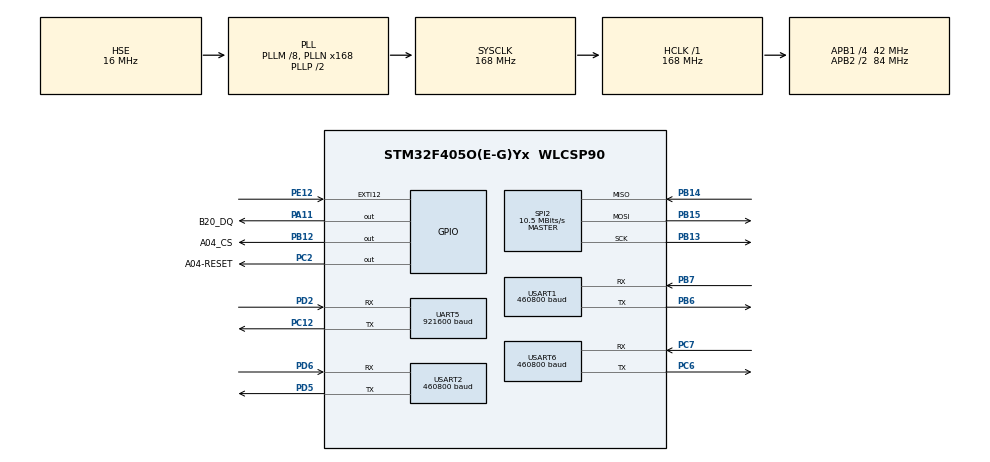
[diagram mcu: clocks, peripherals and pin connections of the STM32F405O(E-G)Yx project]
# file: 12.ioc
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Dma.Request0=USART1_RX
Dma.Request1=USART1_TX
Dma.Request2=USART2_RX
Dma.Request3=USART2_TX
Dma.Request4=USART6_RX
Dma.Request5=USART6_TX
Dma.Request6=SPI2_RX
Dma.Request7=SPI2_TX
Dma.Request8=UART5_RX
Dma.Request9=UART5_TX
Dma.SPI2_RX.6.Direction=DMA_PERIPH_TO_MEMORY
Dma.SPI2_RX.6.FIFOMode=DMA_FIFOMODE_DISABLE
Dma.SPI2_RX.6.Instance=DMA1_Stream3
Dma.SPI2_RX.6.MemDataAlignment=DMA_MDATAALIGN_BYTE
Dma.SPI2_RX.6.MemInc=DMA_MINC_ENABLE
Dma.SPI2_RX.6.Mode=DMA_NORMAL
Dma.SPI2_RX.6.PeriphDataAlignment=DMA_PDATAALIGN_BYTE
Dma.SPI2_RX.6.PeriphInc=DMA_PINC_DISABLE
Dma.SPI2_RX.6.Priority=DMA_PRIORITY_LOW
Dma.SPI2_TX.7.Direction=DMA_MEMORY_TO_PERIPH
Dma.SPI2_TX.7.FIFOMode=DMA_FIFOMODE_DISABLE
Dma.SPI2_TX.7.Instance=DMA1_Stream4
Dma.SPI2_TX.7.MemDataAlignment=DMA_MDATAALIGN_BYTE
Dma.SPI2_TX.7.MemInc=DMA_MINC_ENABLE
Dma.SPI2_TX.7.Mode=DMA_NORMAL
Dma.SPI2_TX.7.PeriphDataAlignment=DMA_PDATAALIGN_BYTE
Dma.SPI2_TX.7.PeriphInc=DMA_PINC_DISABLE
Dma.SPI2_TX.7.Priority=DMA_PRIORITY_LOW
Dma.UART5_RX.8.Direction=DMA_PERIPH_TO_MEMORY
Dma.UART5_RX.8.FIFOMode=DMA_FIFOMODE_DISABLE
Dma.UART5_RX.8.Instance=DMA1_Stream0
Dma.UART5_RX.8.MemDataAlignment=DMA_MDATAALIGN_BYTE
Dma.UART5_RX.8.MemInc=DMA_MINC_ENABLE
Dma.UART5_RX.8.Mode=DMA_NORMAL
Dma.UART5_RX.8.PeriphDataAlignment=DMA_PDATAALIGN_BYTE
Dma.UART5_RX.8.PeriphInc=DMA_PINC_DISABLE
Dma.UART5_RX.8.Priority=DMA_PRIORITY_LOW
Dma.UART5_TX.9.Direction=DMA_MEMORY_TO_PERIPH
Dma.UART5_TX.9.FIFOMode=DMA_FIFOMODE_DISABLE
Dma.UART5_TX.9.Instance=DMA1_Stream7
Dma.UART5_TX.9.MemDataAlignment=DMA_MDATAALIGN_BYTE
Dma.UART5_TX.9.MemInc=DMA_MINC_ENABLE
Dma.UART5_TX.9.Mode=DMA_NORMAL
Dma.UART5_TX.9.PeriphDataAlignment=DMA_PDATAALIGN_BYTE
Dma.UART5_TX.9.PeriphInc=DMA_PINC_DISABLE
Dma.UART5_TX.9.Priority=DMA_PRIORITY_LOW
Dma.USART1_RX.0.Direction=DMA_PERIPH_TO_MEMORY
Dma.USART1_RX.0.FIFOMode=DMA_FIFOMODE_DISABLE
Dma.USART1_RX.0.Instance=DMA2_Stream2
Dma.USART1_RX.0.MemDataAlignment=DMA_MDATAALIGN_BYTE
Dma.USART1_RX.0.MemInc=DMA_MINC_ENABLE
Dma.USART1_RX.0.Mode=DMA_CIRCULAR
Dma.USART1_RX.0.PeriphDataAlignment=DMA_PDATAALIGN_BYTE
Dma.USART1_RX.0.PeriphInc=DMA_PINC_DISABLE
Dma.USART1_RX.0.Priority=DMA_PRIORITY_LOW
Dma.USART1_TX.1.Direction=DMA_MEMORY_TO_PERIPH
Dma.USART1_TX.1.FIFOMode=DMA_FIFOMODE_DISABLE
Dma.USART1_TX.1.Instance=DMA2_Stream7
Dma.USART1_TX.1.MemDataAlignment=DMA_MDATAALIGN_BYTE
Dma.USART1_TX.1.MemInc=DMA_MINC_ENABLE
Dma.USART1_TX.1.Mode=DMA_NORMAL
Dma.USART1_TX.1.PeriphDataAlignment=DMA_PDATAALIGN_BYTE
Dma.USART1_TX.1.PeriphInc=DMA_PINC_DISABLE
Dma.USART1_TX.1.Priority=DMA_PRIORITY_LOW
Dma.USART2_RX.2.Direction=DMA_PERIPH_TO_MEMORY
Dma.USART2_RX.2.FIFOMode=DMA_FIFOMODE_DISABLE
Dma.USART2_RX.2.Instance=DMA1_Stream5
Dma.USART2_RX.2.MemDataAlignment=DMA_MDATAALIGN_BYTE
Dma.USART2_RX.2.MemInc=DMA_MINC_ENABLE
Dma.USART2_RX.2.Mode=DMA_CIRCULAR
Dma.USART2_RX.2.PeriphDataAlignment=DMA_PDATAALIGN_BYTE
Dma.USART2_RX.2.PeriphInc=DMA_PINC_DISABLE
Dma.USART2_RX.2.Priority=DMA_PRIORITY_LOW
Dma.USART2_TX.3.Direction=DMA_MEMORY_TO_PERIPH
Dma.USART2_TX.3.FIFOMode=DMA_FIFOMODE_DISABLE
Dma.USART2_TX.3.Instance=DMA1_Stream6
Dma.USART2_TX.3.MemDataAlignment=DMA_MDATAALIGN_BYTE
Dma.USART2_TX.3.MemInc=DMA_MINC_ENABLE
Dma.USART2_TX.3.Mode=DMA_NORMAL
Dma.USART2_TX.3.PeriphDataAlignment=DMA_PDATAALIGN_BYTE
Dma.USART2_TX.3.PeriphInc=DMA_PINC_DISABLE
Dma.USART2_TX.3.Priority=DMA_PRIORITY_LOW
Dma.USART6_RX.4.Direction=DMA_PERIPH_TO_MEMORY
Dma.USART6_RX.4.FIFOMode=DMA_FIFOMODE_DISABLE
Dma.USART6_RX.4.Instance=DMA2_Stream1
Dma.USART6_RX.4.MemDataAlignment=DMA_MDATAALIGN_BYTE
Dma.USART6_RX.4.MemInc=DMA_MINC_ENABLE
Dma.USART6_RX.4.Mode=DMA_CIRCULAR
Dma.USART6_RX.4.PeriphDataAlignment=DMA_PDATAALIGN_BYTE
Dma.USART6_RX.4.PeriphInc=DMA_PINC_DISABLE
Dma.USART6_RX.4.Priority=DMA_PRIORITY_LOW
Dma.USART6_TX.5.Direction=DMA_MEMORY_TO_PERIPH
Dma.USART6_TX.5.FIFOMode=DMA_FIFOMODE_DISABLE
Dma.USART6_TX.5.Instance=DMA2_Stream6
Dma.USART6_TX.5.MemDataAlignment=DMA_MDATAALIGN_BYTE
Dma.USART6_TX.5.MemInc=DMA_MINC_ENABLE
Dma.USART6_TX.5.Mode=DMA_NORMAL
Dma.USART6_TX.5.PeriphDataAlignment=DMA_PDATAALIGN_BYTE
Dma.USART6_TX.5.PeriphInc=DMA_PINC_DISABLE
Dma.USART6_TX.5.Priority=DMA_PRIORITY_LOW
Mcu.Family=STM32F4
Mcu.Name=STM32F405O(E-G)Yx
Mcu.Package=WLCSP90
NVIC.DMA1_Stream0_IRQn=true\:0\:0\:false\:false\:true\:false\:true\:true
NVIC.DMA1_Stream3_IRQn=true\:0\:0\:false\:false\:true\:false\:true\:true
NVIC.DMA1_Stream4_IRQn=true\:0\:0\:false\:false\:true\:false\:true\:true
NVIC.DMA1_Stream5_IRQn=true\:0\:0\:false\:false\:true\:false\:true\:true
NVIC.DMA1_Stream6_IRQn=true\:0\:0\:false\:false\:true\:false\:true\:true
NVIC.DMA1_Stream7_IRQn=true\:0\:0\:false\:false\:true\:false\:true\:true
NVIC.DMA2_Stream1_IRQn=true\:0\:0\:false\:false\:true\:false\:true\:true
NVIC.DMA2_Stream2_IRQn=true\:0\:0\:false\:false\:true\:false\:true\:true
NVIC.DMA2_Stream6_IRQn=true\:0\:0\:false\:false\:true\:false\:true\:true
NVIC.DMA2_Stream7_IRQn=true\:0\:0\:false\:false\:true\:false\:true\:true
NVIC.EXTI15_10_IRQn=true\:1\:0\:true\:false\:true\:true\:true\:true
NVIC.PriorityGroup=NVIC_PRIORITYGROUP_4
NVIC.SPI2_IRQn=true\:0\:0\:false\:false\:true\:true\:true\:true
NVIC.TIM2_IRQn=true\:0\:0\:true\:false\:true\:true\:true\:true
NVIC.UART5_IRQn=true\:0\:0\:false\:false\:true\:true\:true\:true
NVIC.USART1_IRQn=true\:0\:0\:true\:false\:true\:true\:true\:true
NVIC.USART2_IRQn=true\:0\:0\:true\:false\:true\:true\:true\:true
NVIC.USART6_IRQn=true\:0\:0\:true\:false\:true\:true\:true\:true
PA11.GPIO_Label=B20_DQ
PA11.Signal=GPIO_Output
PB12.GPIO_Label=A04_CS
PB12.Signal=GPIO_Output
PB13.Mode=Full_Duplex_Master
PB13.Signal=SPI2_SCK
PB14.Mode=Full_Duplex_Master
PB14.Signal=SPI2_MISO
PB15.Mode=Full_Duplex_Master
PB15.Signal=SPI2_MOSI
PB6.Mode=Asynchronous
PB6.Signal=USART1_TX
PB7.Mode=Asynchronous
PB7.Signal=USART1_RX
PC12.Mode=Asynchronous
PC12.Signal=UART5_TX
PC14-OSC32_IN.Mode=LSE-External-Oscillator
PC14-OSC32_IN.Signal=RCC_OSC32_IN
PC15-OSC32_OUT.Mode=LSE-External-Oscillator
PC15-OSC32_OUT.Signal=RCC_OSC32_OUT
PC2.GPIO_Label=A04-RESET
PC2.Signal=GPIO_Output
PC6.Mode=Asynchronous
PC6.Signal=USART6_TX
PC7.Mode=Asynchronous
PC7.Signal=USART6_RX
PD2.Mode=Asynchronous
PD2.Signal=UART5_RX
PD5.Mode=Asynchronous
PD5.Signal=USART2_TX
PD6.Mode=Asynchronous
PD6.Signal=USART2_RX
PE12.GPIO_ModeDefaultEXTI=GPIO_MODE_IT_FALLING
PE12.Signal=GPXTI12
PH0-OSC_IN.Mode=HSE-External-Oscillator
PH0-OSC_IN.Signal=RCC_OSC_IN
PH1-OSC_OUT.Mode=HSE-External-Oscillator
PH1-OSC_OUT.Signal=RCC_OSC_OUT
ProjectManager.HeapSize=0x200
ProjectManager.StackSize=0x400
ProjectManager.TargetToolchain=MDK-ARM V5.32
RCC.48MHZClocksFreq_Value=84000000
RCC.AHBFreq_Value=168000000
RCC.APB1CLKDivider=RCC_HCLK_DIV4
RCC.APB1Freq_Value=42000000
RCC.APB1TimFreq_Value=84000000
RCC.APB2CLKDivider=RCC_HCLK_DIV2
RCC.APB2Freq_Value=84000000
RCC.APB2TimFreq_Value=168000000
RCC.CortexFreq_Value=168000000
RCC.HCLKFreq_Value=168000000
RCC.HSE_VALUE=16000000
RCC.HSI_VALUE=16000000
RCC.PLLM=8
RCC.PLLN=168
RCC.PLLSourceVirtual=RCC_PLLSOURCE_HSE
RCC.SYSCLKFreq_VALUE=168000000
RCC.SYSCLKSource=RCC_SYSCLKSOURCE_PLLCLK
RCC.VCOOutputFreq_Value=336000000
SPI2.BaudRatePrescaler=SPI_BAUDRATEPRESCALER_4
SPI2.CLKPhase=SPI_PHASE_2EDGE
SPI2.CalculateBaudRate=10.5 MBits/s
SPI2.Direction=SPI_DIRECTION_2LINES
SPI2.Mode=SPI_MODE_MASTER
SPI2.VirtualType=VM_MASTER
TIM2.Period=999
TIM2.Prescaler=83
UART5.BaudRate=921600
UART5.VirtualMode=Asynchronous
USART1.BaudRate=460800
USART1.VirtualMode=VM_ASYNC
USART2.BaudRate=460800
USART2.VirtualMode=VM_ASYNC
USART6.BaudRate=460800
USART6.VirtualMode=VM_ASYNC
VP_TIM2_VS_ClockSourceINT.Mode=Internal
board=custom

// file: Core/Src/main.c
/* USER CODE BEGIN Header */
/**
  ******************************************************************************
  * @file           : main.c
  * @brief          : Main program body
  ******************************************************************************
  * @attention
  *
  * Copyright (c) 2025 STMicroelectronics.
  * All rights reserved.
  *
  * This software is licensed under terms that can be found in the LICENSE file
  * in the root directory of this software component.
  * If no LICENSE file comes with this software, it is provided AS-IS.
  *
  ******************************************************************************
  */
/* USER CODE END Header */
#include "main.h"
#include "dma.h"
#include "spi.h"
#include "tim.h"
#include "usart.h"
#include "gpio.h"

/* USER CODE BEGIN Includes */
#include "A04_spi.h"
#include "ds_18b20.h"
/* USER CODE END Includes */

void SystemClock_Config(void);

/* USER CODE BEGIN 0 */
uint8_t rxBuf[10];
uint8_t rxBuf_1[10];
uint8_t rxBuf_2[10];
float tempreature= 0;
/* USER CODE END 0 */

int main(void)
{

  /* MCU Configuration--------------------------------------------------------*/

  /* Reset of all peripherals, Initializes the Flash interface and the Systick. */
  HAL_Init();

  /* Configure the system clock */
  SystemClock_Config();

  /* Initialize all configured peripherals */
  MX_GPIO_Init();
  MX_DMA_Init();
  MX_USART1_UART_Init();
  MX_TIM2_Init();
  MX_USART2_UART_Init();
  MX_USART6_UART_Init();
  MX_SPI2_Init();
  MX_UART5_Init();
  /* USER CODE BEGIN 2 */

	HAL_UART_Receive_DMA(&huart1, rxBuf, 10);
	HAL_UART_Receive_DMA(&huart2, rxBuf_1, 10);
	HAL_UART_Receive_DMA(&huart6, rxBuf_2, 10);

	ADS131A04_Init();
	DS18B20_Init();
	HAL_TIM_Base_Start_IT(&htim2);
  /* USER CODE END 2 */

  /* Infinite loop */
  while (1)
  {

    /* USER CODE BEGIN 3 */

		tempreature = DS18B20_Get_Temperature_float();
  }
  /* USER CODE END 3 */
}

void SystemClock_Config(void)
{
  RCC_OscInitTypeDef RCC_OscInitStruct = {0};
  RCC_ClkInitTypeDef RCC_ClkInitStruct = {0};

  /** Configure the main internal regulator output voltage
  */
  __HAL_RCC_PWR_CLK_ENABLE();
  __HAL_PWR_VOLTAGESCALING_CONFIG(PWR_REGULATOR_VOLTAGE_SCALE1);

  /** Initializes the RCC Oscillators according to the specified parameters
  * in the RCC_OscInitTypeDef structure.
  */
  RCC_OscInitStruct.OscillatorType = RCC_OSCILLATORTYPE_HSE;
  RCC_OscInitStruct.HSEState = RCC_HSE_ON;
  RCC_OscInitStruct.PLL.PLLState = RCC_PLL_ON;
  RCC_OscInitStruct.PLL.PLLSource = RCC_PLLSOURCE_HSE;
  RCC_OscInitStruct.PLL.PLLM = 8;
  RCC_OscInitStruct.PLL.PLLN = 168;
  RCC_OscInitStruct.PLL.PLLP = RCC_PLLP_DIV2;
  RCC_OscInitStruct.PLL.PLLQ = 4;
  if (HAL_RCC_OscConfig(&RCC_OscInitStruct) != HAL_OK)
  {
    Error_Handler();
  }

  /** Initializes the CPU, AHB and APB buses clocks
  */
  RCC_ClkInitStruct.ClockType = RCC_CLOCKTYPE_HCLK|RCC_CLOCKTYPE_SYSCLK
                              |RCC_CLOCKTYPE_PCLK1|RCC_CLOCKTYPE_PCLK2;
  RCC_ClkInitStruct.SYSCLKSource = RCC_SYSCLKSOURCE_PLLCLK;
  RCC_ClkInitStruct.AHBCLKDivider = RCC_SYSCLK_DIV1;
  RCC_ClkInitStruct.APB1CLKDivider = RCC_HCLK_DIV4;
  RCC_ClkInitStruct.APB2CLKDivider = RCC_HCLK_DIV2;

  if (HAL_RCC_ClockConfig(&RCC_ClkInitStruct, FLASH_LATENCY_5) != HAL_OK)
  {
    Error_Handler();
  }
}

void Error_Handler(void)
{
  __disable_irq();
  while (1)
  {
  }
}
